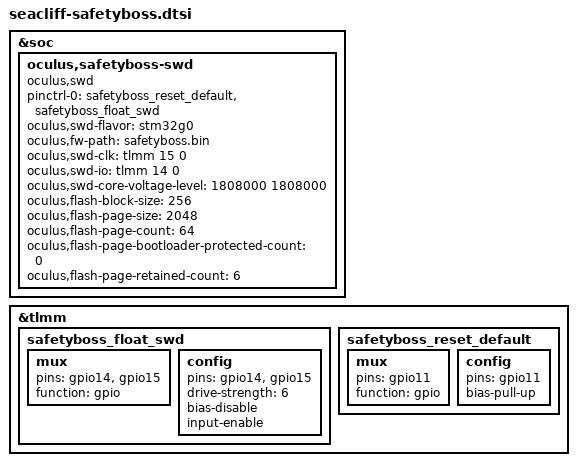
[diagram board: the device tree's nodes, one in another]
&soc {
	oculus,safetyboss-swd {
		compatible = "oculus,swd";

		pinctrl-names = "default";
		pinctrl-0 = <&safetyboss_reset_default &safetyboss_float_swd>;

		oculus,swd-flavor = "stm32g0";
		oculus,fw-path = "safetyboss.bin";
		oculus,swd-clk = <&tlmm 15 0>;
		oculus,swd-io  = <&tlmm 14 0>;
		oculus,swd-core-voltage-level = <1808000 1808000>;
		oculus,flash-block-size = <256>;
		oculus,flash-page-size = <2048>;
		oculus,flash-page-count = <64>;
		oculus,flash-page-bootloader-protected-count = <0>;
		oculus,flash-page-retained-count = <6>;
	};
};


&tlmm {
	// 11 = NRESET
	// 14 = SWDIO
	// 15 = SWDCLK
	safetyboss_float_swd: safetyboss_float_swd {
		mux {
			pins = "gpio14", "gpio15";
			function = "gpio";
		};

		config {
			pins = "gpio14", "gpio15";
			drive-strength = <6>;
			bias-disable;
			input-enable;
		};
	};

	safetyboss_reset_default: safetyboss_reset_default {
		mux {
			pins = "gpio11";
			function = "gpio";
		};

		config {
			pins = "gpio11";
			// Reset is active-low - pull up to avoid
			// keeping it in reset
			bias-pull-up;
		};
	};
};
